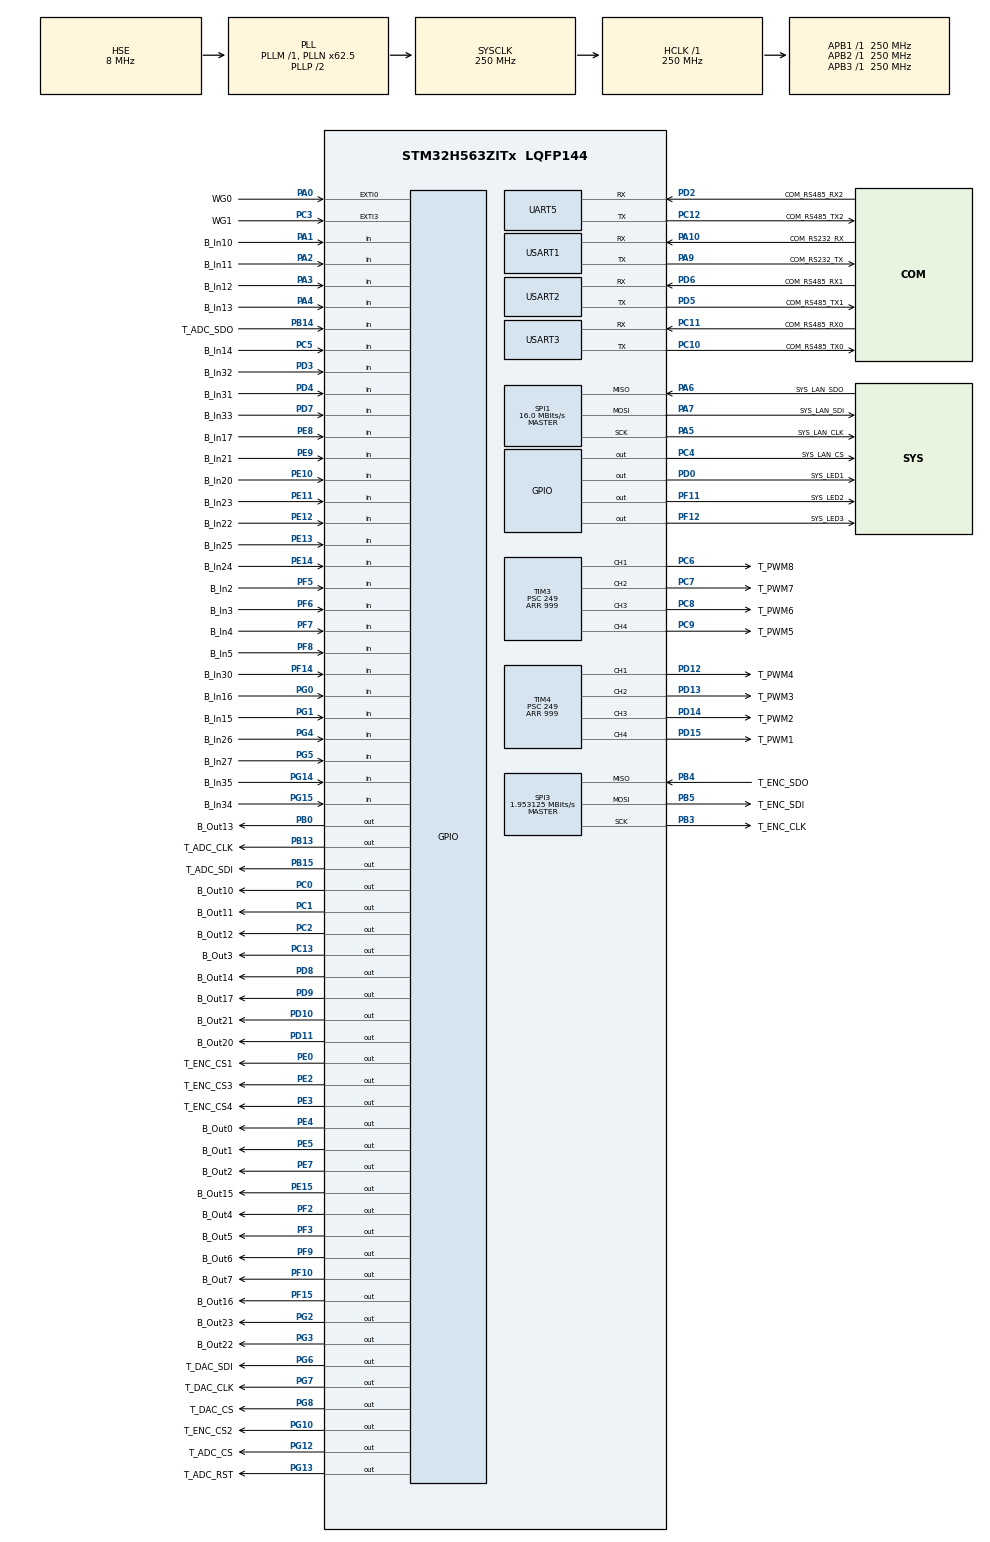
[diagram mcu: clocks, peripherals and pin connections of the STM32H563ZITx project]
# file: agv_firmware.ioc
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BOOTPATH.BootPathName=LEGACY
BOOTPATH.UserSelectedBootPath=LEGACY
CORTEX_M33_NS.userName=CORTEX_M33
GPDMA1.CIRCULARMODE_GPDMACH0=ENABLE
GPDMA1.CIRCULARMODE_GPDMACH1=ENABLE
GPDMA1.CIRCULARMODE_GPDMACH2=ENABLE
GPDMA1.CIRCULARMODE_GPDMACH3=ENABLE
GPDMA1.DESTINC_GPDMACH0=DMA_DINC_INCREMENTED
GPDMA1.DESTINC_GPDMACH1=DMA_DINC_INCREMENTED
GPDMA1.DESTINC_GPDMACH2=DMA_DINC_INCREMENTED
GPDMA1.DESTINC_GPDMACH3=DMA_DINC_INCREMENTED
GPDMA1.IPHANDLE_GPDMACH0-SIMPLEREQUEST_GPDMACH0=__NULL
GPDMA1.IPHANDLE_GPDMACH1-SIMPLEREQUEST_GPDMACH1=__NULL
GPDMA1.IPHANDLE_GPDMACH2-SIMPLEREQUEST_GPDMACH2=__NULL
GPDMA1.IPHANDLE_GPDMACH3-SIMPLEREQUEST_GPDMACH3=__NULL
GPDMA1.LINKALLOCATEDPORT_CIRCULAR_GPDMACH1=DMA_LINK_ALLOCATED_PORT1
GPDMA1.REQUEST_GPDMACH0=GPDMA1_REQUEST_USART3_RX
GPDMA1.REQUEST_GPDMACH1=GPDMA1_REQUEST_USART2_RX
GPDMA1.REQUEST_GPDMACH2=GPDMA1_REQUEST_UART5_RX
GPDMA1.REQUEST_GPDMACH3=GPDMA1_REQUEST_USART1_RX
GPDMA1.SRCINC_GPDMACH0=DMA_SINC_INCREMENTED
GPDMA1.SRCINC_GPDMACH3=DMA_SINC_FIXED
Mcu.Family=STM32H5
Mcu.Name=STM32H563ZITx
Mcu.Package=LQFP144
NVIC.EXTI0_IRQn=true\:0\:0\:false\:false\:true\:true\:true\:true
NVIC.EXTI3_IRQn=true\:0\:0\:false\:false\:true\:true\:true\:true
NVIC.GPDMA1_Channel0_IRQn=true\:0\:0\:false\:false\:true\:false\:true\:true
NVIC.GPDMA1_Channel1_IRQn=true\:0\:0\:false\:false\:true\:false\:true\:true
NVIC.GPDMA1_Channel2_IRQn=true\:0\:0\:false\:false\:true\:false\:true\:true
NVIC.GPDMA1_Channel3_IRQn=true\:0\:0\:false\:false\:true\:false\:true\:true
NVIC.PriorityGroup=NVIC_PRIORITYGROUP_4
NVIC.TIM3_IRQn=true\:0\:0\:false\:false\:true\:true\:true\:true
NVIC.TIM6_IRQn=true\:0\:0\:false\:false\:true\:true\:true\:true
NVIC.TIM7_IRQn=true\:3\:0\:true\:false\:true\:true\:true\:true
NVIC.UART5_IRQn=true\:0\:0\:false\:false\:true\:true\:true\:true
NVIC.USART1_IRQn=true\:0\:0\:false\:false\:true\:true\:true\:true
NVIC.USART2_IRQn=true\:0\:0\:false\:false\:true\:true\:true\:true
NVIC.USART3_IRQn=true\:0\:0\:false\:false\:true\:true\:true\:true
PA0.GPIO_Label=WG0
PA0.GPIO_ModeDefaultEXTI=GPIO_MODE_IT_FALLING
PA0.GPIO_PuPd=GPIO_PULLUP
PA0.Signal=GPXTI0
PA1.GPIO_Label=B_In10
PA1.Signal=GPIO_Input
PA10.GPIO_Label=COM_RS232_RX
PA10.Mode=Asynchronous
PA10.Signal=USART1_RX
PA13(JTMS/SWDIO).Mode=Serial_Wire
PA13(JTMS/SWDIO).Signal=DEBUG_JTMS-SWDIO
PA14(JTCK/SWCLK).Mode=Serial_Wire
PA14(JTCK/SWCLK).Signal=DEBUG_JTCK-SWCLK
PA2.GPIO_Label=B_In11
PA2.Signal=GPIO_Input
PA3.GPIO_Label=B_In12
PA3.Signal=GPIO_Input
PA4.GPIO_Label=B_In13
PA4.Signal=GPIO_Input
PA5.GPIO_Label=SYS_LAN_CLK
PA5.Mode=Full_Duplex_Master
PA5.Signal=SPI1_SCK
PA6.GPIO_Label=SYS_LAN_SDO
PA6.Mode=Full_Duplex_Master
PA6.Signal=SPI1_MISO
PA7.GPIO_Label=SYS_LAN_SDI
PA7.Mode=Full_Duplex_Master
PA7.Signal=SPI1_MOSI
PA9.GPIO_Label=COM_RS232_TX
PA9.Mode=Asynchronous
PA9.Signal=USART1_TX
PB0.GPIO_Label=B_Out13
PB0.Signal=GPIO_Output
PB13.GPIO_Label=T_ADC_CLK
PB13.Signal=GPIO_Output
PB14.GPIO_Label=T_ADC_SDO
PB14.GPIO_PuPd=GPIO_PULLUP
PB14.Signal=GPIO_Input
PB15.GPIO_Label=T_ADC_SDI
PB15.Signal=GPIO_Output
PB3(JTDO/TRACESWO).GPIO_Label=T_ENC_CLK
PB3(JTDO/TRACESWO).GPIO_Speed=GPIO_SPEED_FREQ_VERY_HIGH
PB3(JTDO/TRACESWO).Mode=Full_Duplex_Master
PB3(JTDO/TRACESWO).Signal=SPI3_SCK
PB4(NJTRST).GPIO_Label=T_ENC_SDO
PB4(NJTRST).GPIO_Speed=GPIO_SPEED_FREQ_VERY_HIGH
PB4(NJTRST).Mode=Full_Duplex_Master
PB4(NJTRST).Signal=SPI3_MISO
PB5.GPIO_Label=T_ENC_SDI
PB5.GPIO_Speed=GPIO_SPEED_FREQ_VERY_HIGH
PB5.Mode=Full_Duplex_Master
PB5.Signal=SPI3_MOSI
PC0.GPIO_Label=B_Out10
PC0.Signal=GPIO_Output
PC1.GPIO_Label=B_Out11
PC1.Signal=GPIO_Output
PC10.GPIO_Label=COM_RS485_TX0
PC10.Mode=Asynchronous
PC10.Signal=USART3_TX
PC11.GPIO_Label=COM_RS485_RX0
PC11.Mode=Asynchronous
PC11.Signal=USART3_RX
PC12.GPIO_Label=COM_RS485_TX2
PC12.Mode=Asynchronous
PC12.Signal=UART5_TX
PC13.GPIO_Label=B_Out3
PC13.Signal=GPIO_Output
PC2.GPIO_Label=B_Out12
PC2.Signal=GPIO_Output
PC3.GPIO_Label=WG1
PC3.GPIO_ModeDefaultEXTI=GPIO_MODE_IT_FALLING
PC3.GPIO_PuPd=GPIO_PULLUP
PC3.Signal=GPXTI3
PC4.GPIO_Label=SYS_LAN_CS
PC4.Signal=GPIO_Output
PC5.GPIO_Label=B_In14
PC5.Signal=GPIO_Input
PC6.GPIO_Label=T_PWM8
PC6.Signal=S_TIM3_CH1
PC7.GPIO_Label=T_PWM7
PC7.Signal=S_TIM3_CH2
PC8.GPIO_Label=T_PWM6
PC8.Signal=S_TIM3_CH3
PC9.GPIO_Label=T_PWM5
PC9.Signal=S_TIM3_CH4
PD0.GPIO_Label=SYS_LED1
PD0.Signal=GPIO_Output
PD10.GPIO_Label=B_Out21
PD10.Signal=GPIO_Output
PD11.GPIO_Label=B_Out20
PD11.Signal=GPIO_Output
PD12.GPIO_Label=T_PWM4
PD12.Signal=S_TIM4_CH1
PD13.GPIO_Label=T_PWM3
PD13.PinAttribute=Free
PD13.Signal=S_TIM4_CH2
PD14.GPIO_Label=T_PWM2
PD14.Signal=S_TIM4_CH3
PD15.GPIO_Label=T_PWM1
PD15.Signal=S_TIM4_CH4
PD2.GPIO_Label=COM_RS485_RX2
PD2.Mode=Asynchronous
PD2.Signal=UART5_RX
PD3.GPIO_Label=B_In32
PD3.GPIO_PuPd=GPIO_PULLUP
PD3.Signal=GPIO_Input
PD4.GPIO_Label=B_In31
PD4.GPIO_PuPd=GPIO_PULLUP
PD4.Signal=GPIO_Input
PD5.GPIO_Label=COM_RS485_TX1
PD5.Mode=Asynchronous
PD5.Signal=USART2_TX
PD6.GPIO_Label=COM_RS485_RX1
PD6.Mode=Asynchronous
PD6.Signal=USART2_RX
PD7.GPIO_Label=B_In33
PD7.GPIO_PuPd=GPIO_PULLUP
PD7.Signal=GPIO_Input
PD8.GPIO_Label=B_Out14
PD8.Signal=GPIO_Output
PD9.GPIO_Label=B_Out17
PD9.Signal=GPIO_Output
PE0.GPIO_Label=T_ENC_CS1
PE0.GPIO_Speed=GPIO_SPEED_FREQ_VERY_HIGH
PE0.Signal=GPIO_Output
PE10.GPIO_Label=B_In20
PE10.GPIO_PuPd=GPIO_PULLUP
PE10.Signal=GPIO_Input
PE11.GPIO_Label=B_In23
PE11.GPIO_PuPd=GPIO_PULLUP
PE11.Signal=GPIO_Input
PE12.GPIO_Label=B_In22
PE12.GPIO_PuPd=GPIO_PULLUP
PE12.Signal=GPIO_Input
PE13.GPIO_Label=B_In25
PE13.GPIO_PuPd=GPIO_PULLUP
PE13.Signal=GPIO_Input
PE14.GPIO_Label=B_In24
PE14.GPIO_PuPd=GPIO_PULLUP
PE14.Signal=GPIO_Input
PE15.GPIO_Label=B_Out15
PE15.Signal=GPIO_Output
PE2.GPIO_Label=T_ENC_CS3
PE2.GPIO_Speed=GPIO_SPEED_FREQ_VERY_HIGH
PE2.Signal=GPIO_Output
PE3.GPIO_Label=T_ENC_CS4
PE3.GPIO_Speed=GPIO_SPEED_FREQ_VERY_HIGH
PE3.Signal=GPIO_Output
PE4.GPIO_Label=B_Out0
PE4.Signal=GPIO_Output
PE5.GPIO_Label=B_Out1
PE5.Signal=GPIO_Output
PE7.GPIO_Label=B_Out2
PE7.Signal=GPIO_Output
PE8.GPIO_Label=B_In17
PE8.GPIO_PuPd=GPIO_PULLUP
PE8.Signal=GPIO_Input
PE9.GPIO_Label=B_In21
PE9.GPIO_PuPd=GPIO_PULLUP
PE9.Signal=GPIO_Input
PF10.GPIO_Label=B_Out7
PF10.Signal=GPIO_Output
PF11.GPIO_Label=SYS_LED2
PF11.Signal=GPIO_Output
PF12.GPIO_Label=SYS_LED3
PF12.Signal=GPIO_Output
PF14.GPIO_Label=B_In30
PF14.GPIO_PuPd=GPIO_PULLUP
PF14.Signal=GPIO_Input
PF15.GPIO_Label=B_Out16
PF15.Signal=GPIO_Output
PF2.GPIO_Label=B_Out4
PF2.Signal=GPIO_Output
PF3.GPIO_Label=B_Out5
PF3.Signal=GPIO_Output
PF5.GPIO_Label=B_In2
PF5.Signal=GPIO_Input
PF6.GPIO_Label=B_In3
PF6.Signal=GPIO_Input
PF7.GPIO_Label=B_In4
PF7.Signal=GPIO_Input
PF8.GPIO_Label=B_In5
PF8.Signal=GPIO_Input
PF9.GPIO_Label=B_Out6
PF9.Signal=GPIO_Output
PG0.GPIO_Label=B_In16
PG0.GPIO_PuPd=GPIO_PULLUP
PG0.Signal=GPIO_Input
PG1.GPIO_Label=B_In15
PG1.Signal=GPIO_Input
PG10.GPIO_Label=T_ENC_CS2
PG10.GPIO_Speed=GPIO_SPEED_FREQ_VERY_HIGH
PG10.Signal=GPIO_Output
PG12.GPIO_Label=T_ADC_CS
PG12.Signal=GPIO_Output
PG13.GPIO_Label=T_ADC_RST
PG13.Signal=GPIO_Output
PG14.GPIO_Label=B_In35
PG14.GPIO_Mode=GPIO_MODE_INPUT
PG14.GPIO_PuPd=GPIO_PULLUP
PG14.Signal=GPIO_Input
PG15.GPIO_Label=B_In34
PG15.GPIO_Mode=GPIO_MODE_INPUT
PG15.GPIO_PuPd=GPIO_PULLUP
PG15.Signal=GPIO_Input
PG2.GPIO_Label=B_Out23
PG2.Signal=GPIO_Output
PG3.GPIO_Label=B_Out22
PG3.Signal=GPIO_Output
PG4.GPIO_Label=B_In26
PG4.GPIO_PuPd=GPIO_PULLUP
PG4.Signal=GPIO_Input
PG5.GPIO_Label=B_In27
PG5.GPIO_PuPd=GPIO_PULLUP
PG5.Signal=GPIO_Input
PG6.GPIO_Label=T_DAC_SDI
PG6.Signal=GPIO_Output
PG7.GPIO_Label=T_DAC_CLK
PG7.Signal=GPIO_Output
PG8.GPIO_Label=T_DAC_CS
PG8.Signal=GPIO_Output
PH0-OSC_IN(PH0).Mode=HSE-External-Oscillator
PH0-OSC_IN(PH0).Signal=RCC_OSC_IN
PH1-OSC_OUT(PH1).Mode=HSE-External-Oscillator
PH1-OSC_OUT(PH1).Signal=RCC_OSC_OUT
ProjectManager.HeapSize=0x200
ProjectManager.StackSize=0x400
ProjectManager.TargetToolchain=STM32CubeIDE
RCC.ADCFreq_Value=250000000
RCC.AHBFreq_Value=250000000
RCC.APB1Freq_Value=250000000
RCC.APB1TimFreq_Value=250000000
RCC.APB2Freq_Value=250000000
RCC.APB2TimFreq_Value=250000000
RCC.APB3Freq_Value=250000000
RCC.CSI_VALUE=4000000
RCC.CortexFreq_Value=250000000
RCC.EPOD_VALUE=8000000
RCC.EnbaleCSS=true
RCC.HCLKFreq_Value=250000000
RCC.HSE_VALUE=8000000
RCC.HSI48_VALUE=48000000
RCC.HSI_VALUE=64000000
RCC.LSE_VALUE=32768
RCC.LSIRC_VALUE=32000
RCC.PLL1Q=4
RCC.PLL2FRACN=0
RCC.PLL3FRACN=0
RCC.PLLFRACN=4096
RCC.PLLN=62
RCC.PLLSourceVirtual=RCC_PLL1_SOURCE_HSE
RCC.SPI1CLockSelection=RCC_SPI1CLKSOURCE_CLKP
RCC.SYSCLKFreq_VALUE=250000000
RCC.SYSCLKSource=RCC_SYSCLKSOURCE_PLLCLK
RCC.USBFreq_Value=48000000
RCC.VCOOutputFreq_Value=500000000
SH.S_TIM3_CH1.0=TIM3_CH1,PWM Generation1 CH1
SH.S_TIM3_CH2.0=TIM3_CH2,PWM Generation2 CH2
SH.S_TIM3_CH3.0=TIM3_CH3,PWM Generation3 CH3
SH.S_TIM3_CH4.0=TIM3_CH4,PWM Generation4 CH4
SH.S_TIM4_CH1.0=TIM4_CH1,PWM Generation1 CH1
SH.S_TIM4_CH2.0=TIM4_CH2,PWM Generation2 CH2
SH.S_TIM4_CH3.0=TIM4_CH3,PWM Generation3 CH3
SH.S_TIM4_CH4.0=TIM4_CH4,PWM Generation4 CH4
SPI1.CalculateBaudRate=16.0 MBits/s
SPI1.Direction=SPI_DIRECTION_2LINES
SPI1.Mode=SPI_MODE_MASTER
SPI1.VirtualType=VM_MASTER
SPI3.BaudRatePrescaler=SPI_BAUDRATEPRESCALER_64
SPI3.CalculateBaudRate=1.953125 MBits/s
SPI3.DataSize=SPI_DATASIZE_8BIT
SPI3.Direction=SPI_DIRECTION_2LINES
SPI3.Mode=SPI_MODE_MASTER
SPI3.VirtualType=VM_MASTER
TIM3.AutoReloadPreload=TIM_AUTORELOAD_PRELOAD_ENABLE
TIM3.Channel-PWM\ Generation1\ CH1=TIM_CHANNEL_1
TIM3.Channel-PWM\ Generation2\ CH2=TIM_CHANNEL_2
TIM3.Channel-PWM\ Generation3\ CH3=TIM_CHANNEL_3
TIM3.Channel-PWM\ Generation4\ CH4=TIM_CHANNEL_4
TIM3.PeriodNoDither=999
TIM3.Prescaler=249
TIM4.Channel-PWM\ Generation1\ CH1=TIM_CHANNEL_1
TIM4.Channel-PWM\ Generation2\ CH2=TIM_CHANNEL_2
TIM4.Channel-PWM\ Generation3\ CH3=TIM_CHANNEL_3
TIM4.Channel-PWM\ Generation4\ CH4=TIM_CHANNEL_4
TIM4.PeriodNoDither=999
TIM4.Prescaler=249
TIM6.PeriodNoDither=9999
TIM6.Prescaler=249
TIM7.PeriodNoDither=9999
TIM7.Prescaler=249
USART1.VirtualMode-Asynchronous=VM_ASYNC
USART2.VirtualMode-Asynchronous=VM_ASYNC
USART3.VirtualMode-Asynchronous=VM_ASYNC
VP_BOOTPATH_VS_BOOTPATH.Mode=BP_Activate
VP_CORTEX_M33_NS_VS_Hclk.Mode=Hclk_Mode
VP_GPDMA1_VS_GPDMACH0.Mode=SIMPLEREQUEST_GPDMACH0
VP_GPDMA1_VS_GPDMACH1.Mode=SIMPLEREQUEST_GPDMACH1
VP_GPDMA1_VS_GPDMACH2.Mode=SIMPLEREQUEST_GPDMACH2
VP_GPDMA1_VS_GPDMACH3.Mode=SIMPLEREQUEST_GPDMACH3
VP_ICACHE_VS_ENABLE_ICACHE_MEMORY.Mode=Memoryregions
VP_MEMORYMAP_VS_MEMORYMAP.Mode=CurAppReg
VP_PWR_VS_LPOM.Mode=PowerOptimisation
VP_PWR_VS_SECSignals.Mode=Security/Privilege
VP_TIM3_VS_ClockSourceINT.Mode=Internal
VP_TIM6_VS_ClockSourceINT.Mode=Enable_Timer
VP_TIM7_VS_ClockSourceINT.Mode=Enable_Timer
board=custom

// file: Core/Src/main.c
/* USER CODE BEGIN Header */
/**
 ******************************************************************************
 * @file           : main.c
 * @brief          : Main program body
 ******************************************************************************
 * @attention
 *
 * Copyright (c) 2026 STMicroelectronics.
 * All rights reserved.
 *
 * This software is licensed under terms that can be found in the LICENSE file
 * in the root directory of this software component.
 * If no LICENSE file comes with this software, it is provided AS-IS.
 *
 ******************************************************************************
 */
/* USER CODE END Header */
#include "main.h"
#include "gpdma.h"
#include "gpio.h"
#include "icache.h"
#include "spi.h"
#include "tim.h"
#include "usart.h"

/* USER CODE BEGIN Includes */
#include "agv_control.h"
#include "agv_eeprom.h"
#include "agv_routing.h"
#include "esp32_hub.h" // Thư viện giao tiếp ESP32
#include "hmi_modbus.h"
#include "qr50_reader.h"

// #include "wiegand.h"
#include "agv_eeprom.h"
#include "ls7366r.h"
#include "motor.h"
#include "sensor.h"
#include "ads8688.h"
#include <agv_body_step.h>
#include <stdlib.h> // Để sử dụng hàm atoi
#include <string.h>

/* USER CODE END Includes */

/* USER CODE BEGIN PTD */
volatile uint32_t spi_test_result_e1 = 0;
volatile uint32_t spi_test_result_e2 = 0;
/* USER CODE END PTD */

/* USER CODE BEGIN PV */
volatile uint32_t dbg_huart3_rx_byte_count   = 0;
volatile uint32_t dbg_huart3_rx_ok           = 0;
volatile uint32_t dbg_huart3_rx_err          = 0;
volatile uint8_t  huart3_rx_byte             = 0;
volatile float    dbg_huart3_joints_left[6]  = {0.0f};
volatile float    dbg_huart3_joints_right[6] = {0.0f};
volatile char     dbg_huart3_last_type       = 0;

static char       huart3_rx_line[128];
static uint8_t    huart3_rx_line_idx         = 0;

// Các biến phục vụ việc xem trực tiếp trên Live Expression
volatile uint32_t debug_rfid_rx_count = 0;
volatile uint16_t debug_rfid_rx_len = 0;
volatile uint8_t debug_rfid_rx_buf[64] = {0};
volatile uint32_t debug_rfid_err_count = 0;
volatile uint8_t debug_rx_byte = 0;      // Byte nhận tạm thời cho ngắt IT
volatile uint32_t debug_qr_rx_count = 0; // Đếm số lần nhảy vào ngắt nhận QR50
volatile uint32_t debug_qr_err_count = 0; // Đếm số lần bị lỗi khung truyền (Baudrate)
volatile uint32_t debug_hmi_rx_count = 0; // Đếm số lần nhận được ngắt từ HMI
float adc_feedback_ch0 = 0.0f;
volatile uint32_t dbg_tim7_count = 0;       // Đếm số lần TIM7 ISR chạy
volatile uint16_t dbg_ads_raw0 = 0;         // Giá trị ADC thô CH0
volatile uint16_t dbg_ads_raw1 = 0;         // Giá trị ADC thô CH1
volatile uint8_t  dbg_ads_spi_test = 0xFF;  // Kết quả test SPI (0x06=OK, 0=SPI fail)
volatile uint8_t  dbg_ads_pin_rst = 0;      // PG13 RST: kỳ vọng 1 (HIGH) sau init
volatile uint8_t  dbg_ads_pin_cs  = 0;      // PG12 CS:  kỳ vọng 1 (HIGH, idle)
volatile uint8_t  dbg_ads_pin_sdo = 1;      // PB14 SDO: trạng thái idle của MISO
volatile uint8_t  dbg_ads_scan_results[16] = {0}; // Mảng kết quả tự động scan 16 combo (Kỳ vọng combo đúng trả về 0x06)
// === BIẾN GLOBAL ĐỂ DEBUG TRÊN LIVE EXPRESSION ===
AGV_HandleTypeDef h_agv;
Motor_HandleTypeDef m_left, m_right;
LineSensor_HandleTypeDef line_ss;
Pid_data pid_ctrl;
QR50_Handler_t qr50;
uint8_t qr50_rx_buffer[QR50_MAX_DATA_LEN];
Wiegand_HandleTypeDef h_wiegand;
volatile uint32_t debug_wiegand_id = 0; // ID thẻ Wiegand (Live Expression)
volatile uint32_t debug_wiegand_bit_count = 0; // Số bit nhận được (phải = 34)
volatile uint64_t debug_wiegand_raw =
    0; // Raw 34 bit trước khi decode (để chẩn đoán)
volatile uint32_t debug_wiegand_high32 = 0;
volatile uint32_t debug_wiegand_low32 = 0;
// Step thân robot
volatile step_command_t cmd = {.angle = 0, .rpm = 30};
static step_command_t cmd_prev = {0};

// --- CẤU HÌNH MÃ THẺ RFID CỦA TỪNG TRẠM ---
#define RFID_NODE_0 N00
#define RFID_NODE_1 N01
#define RFID_NODE_2 N02
#define RFID_NODE_3 N03
#define RFID_NODE_4 N04
#define RFID_NODE_5 N05
#define RFID_NODE_6 N06
#define RFID_NODE_7 N07
#define RFID_NODE_8 N08

// Mảng ánh xạ RFID sang Node ID (Chỉ mục là Node ID, giá trị là Wiegand ID)
uint32_t rfid_node_map[MAX_NODES] = {
    [0] = RFID_NODE_0, [1] = RFID_NODE_1, [2] = RFID_NODE_2,
    [3] = RFID_NODE_3, [4] = RFID_NODE_4, [5] = RFID_NODE_5,
    [6] = RFID_NODE_6, [7] = RFID_NODE_7, [8] = RFID_NODE_8,
};
volatile LS7366R_EncoderData_t encoder_data;
ADS8688_HandleTypeDef h_ads8688;
AGV_Map_t factory_map;
AGV_Heading_t current_heading = HEAD_NORTH;
extern AGV_State_t agv_state;
extern AGV_Config_t agv_config;
extern ESP32_SensorData_t esp32_data;
extern HMI_HandleTypeDef h_hmi;

uint16_t current_path[MAX_NODES];
uint16_t path_length = 0;
static uint16_t last_processed_node = 0xFFFF;
char debug_line_binary[17] = "0000000000000000";
uint16_t pending_qr_node = 0xFFFF;
uint32_t blind_zone_end_time = 0;
uint32_t calib_time_offset = 750;
uint32_t calib_time_turn_90 = 3500;
volatile uint32_t mode6_stop_time = 0;

GPIO_TypeDef *sensor_ports[16] = {
    B_In35_GPIO_Port, B_In34_GPIO_Port, B_In33_GPIO_Port, B_In32_GPIO_Port,
    B_In31_GPIO_Port, B_In30_GPIO_Port, B_In27_GPIO_Port, B_In26_GPIO_Port,
    B_In25_GPIO_Port, B_In24_GPIO_Port, B_In23_GPIO_Port, B_In22_GPIO_Port,
    B_In21_GPIO_Port, B_In20_GPIO_Port, B_In17_GPIO_Port, B_In16_GPIO_Port};
uint16_t sensor_pins[16] = {B_In35_Pin, B_In34_Pin, B_In33_Pin, B_In32_Pin,
                            B_In31_Pin, B_In30_Pin, B_In27_Pin, B_In26_Pin,
                            B_In25_Pin, B_In24_Pin, B_In23_Pin, B_In22_Pin,
                            B_In21_Pin, B_In20_Pin, B_In17_Pin, B_In16_Pin};

/* USER CODE END PV */

void SystemClock_Config(void);
void PeriphCommonClock_Config(void);

/* USER CODE BEGIN 0 */
#define AGV_ARM_FORWARD_PERIOD_MS 20u

#if 0
static bool AGV_IsLegacyArmCommand(const char *arm_command) {
  return arm_command != NULL &&
         (arm_command[0] == 'L' || arm_command[0] == 'R') &&
         arm_command[1] == ':';
}

static void AGV_ForwardArmCommand(const char *arm_command) {
  if (arm_command == NULL) {
    return;
  }

  size_t cmd_len = strnlen(arm_command, ESP32_MAX_ARM_CMD_LEN);
  if (cmd_len < 3) {
    return;
  }

  if (!AGV_IsLegacyArmCommand(arm_command)) {
    return;
  }

  uint8_t tx_buffer[ESP32_MAX_ARM_CMD_LEN + 2];
  memcpy(tx_buffer, arm_command, cmd_len);

  if (tx_buffer[cmd_len - 1] != '\n') {
    tx_buffer[cmd_len++] = '\n';
  }

  // Temporarily skipped to prevent unconnected UART3 hang
  // HAL_UART_Transmit(&huart3, tx_buffer, (uint16_t)cmd_len, 50);
}
#endif

static void AGV_HandleEsp32Safety(AGV_HandleTypeDef *hagv,
                                  const ESP32_SensorData_t *safe_esp32_data) {
  if (safe_esp32_data == NULL || hagv == NULL)
    return;

  if (!safe_esp32_data->IsConnected)
    return;

  if (safe_esp32_data->Yaw == 65535.0f ||
      safe_esp32_data->ObstacleDistance == 0xFFFF) {
    if (agv_state.follow_line_enable) {
      agv_state.follow_line_enable = false;
      AGV_Stop(hagv);
    }
    return;
  }

  // --- LOGIC VẬT CẢN (VL53L5CX) ---
  bool is_obstacle = false;
  if (safe_esp32_data->ObstacleDistance < 500) {
    bool is_exception = false;
    // Ngoại trừ các đoạn sát tường: 1->0, 4->3, 7->6
    if (path_length > 0 && agv_state.path_index < path_length - 1) {
      uint16_t current_n = current_path[agv_state.path_index];
      uint16_t next_n = current_path[agv_state.path_index + 1];
      if ((current_n == 1 && next_n == 0) || (current_n == 4 && next_n == 3) ||
          (current_n == 7 && next_n == 6)) {
        is_exception = true;
      }
    }

    if (!is_exception) {
      is_obstacle = true;
    }
  }

  static bool paused_by_obstacle = false;

  if (is_obstacle) {
    if (agv_state.follow_line_enable && agv_state.run_mode == MODE_4_FULL_RUN) {
      agv_state.follow_line_enable = false;
      AGV_Stop(hagv);
      paused_by_obstacle = true;
    }
  } else {
    if (paused_by_obstacle) {
      if (agv_state.run_mode == MODE_4_FULL_RUN) {
        agv_state.follow_line_enable = true; // Đi tiếp khi vật cản rời đi
        // Quan trọng: Reset lại bộ đếm timeout QR 15s để tránh bị báo lỗi mất
        // line ngay lập tức
        agv_state.last_qr_time = HAL_GetTick();
      }
      paused_by_obstacle = false;
    }
  }
}

static void AGV_ServiceEsp32Request(uint32_t *last_esp32_req_time) {
  if (last_esp32_req_time == NULL)
    return;

  if (HAL_GetTick() - *last_esp32_req_time > 20) {
    *last_esp32_req_time = HAL_GetTick();
    uint8_t is_arrived =
        (agv_state.current_node == agv_state.destination_node) ? 1 : 0;
    ESP32_RequestData(agv_state.current_node, is_arrived);
  }
}

static void AGV_ServiceHeartbeat(uint32_t *last_led_time) {
  if (last_led_time == NULL)
    return;

  if (HAL_GetTick() - *last_led_time <= 500)
    return;

  *last_led_time = HAL_GetTick();
  HAL_GPIO_TogglePin(SYS_LED1_GPIO_Port, SYS_LED1_Pin);
  __HAL_UART_CLEAR_FLAG(&huart5, UART_CLEAR_OREF | UART_CLEAR_NEF |
                                     UART_CLEAR_FEF | UART_CLEAR_PEF);

  if (HAL_GetTick() - esp32_data.LastUpdateTick > 2000) {
    extern uint8_t esp32_rx_buffer[128];
    HAL_UART_AbortReceive(&huart5);
    HAL_UARTEx_ReceiveToIdle_DMA(&huart5, esp32_rx_buffer,
                                 sizeof(esp32_rx_buffer));
  }
}

static uint8_t mode5_calib_state = 0;
static uint32_t mode5_calib_start_time = 0;

static bool AGV_HandleMode5Calibration(void) {

  if (!ESP32_GetSafeData().IsConnected) {
    AGV_Stop(&h_agv);
    return true;
  }

  agv_state.follow_line_enable = false;

  if (mode5_calib_start_time == 0)
    mode5_calib_start_time = HAL_GetTick();

  uint32_t elapsed = HAL_GetTick() - mode5_calib_start_time;

  switch (mode5_calib_state) {
  case 0:
    AGV_Stop(&h_agv);
    if (elapsed > 2000) {
      mode5_calib_state++;
      mode5_calib_start_time = HAL_GetTick();
    }
    break;
  case 1:
    Motor_SetSpeed(&m_left, agv_config.turn_speed);
    Motor_SetSpeed(&m_right, agv_config.turn_speed);
    if (elapsed > agv_config.time_forward) {
      mode5_calib_state++;
      mode5_calib_start_time = HAL_GetTick();
    }
    break;
  case 2:
    AGV_Stop(&h_agv);
    if (elapsed > 1000) {
      mode5_calib_state++;
      mode5_calib_start_time = HAL_GetTick();
    }
    break;
  case 3:
    Motor_SetSpeed(&m_left, -agv_config.turn_speed);
    Motor_SetSpeed(&m_right, -agv_config.turn_speed);
    if (elapsed > agv_config.time_forward) {
      mode5_calib_state++;
      mode5_calib_start_time = HAL_GetTick();
    }
    break;
  case 4:
    AGV_Stop(&h_agv);
    if (elapsed > 1000) {
      mode5_calib_state++;
      mode5_calib_start_time = HAL_GetTick();
    }
    break;
  case 5:
    AGV_TurnLeft_IMU(&h_agv, 800, 0.70f);
    mode5_calib_state++;
    mode5_calib_start_time = HAL_GetTick();
    break;
  case 6:
    AGV_Stop(&h_agv);
    if (elapsed > 1000) {
      mode5_calib_state++;
      mode5_calib_start_time = HAL_GetTick();
    }
    break;
  case 7:
    AGV_Turn180_IMU(&h_agv, 0); // 0 = HEAD_NORTH
    mode5_calib_state++;
    mode5_calib_start_time = HAL_GetTick();
    break;
  case 8:
    AGV_Stop(&h_agv);
    if (elapsed > 1000) {
      mode5_calib_state++;
      mode5_calib_start_time = HAL_GetTick();
    }
    break;
  case 9:
    Motor_SetSpeed(&m_left, -agv_config.turn_speed);
    Motor_SetSpeed(&m_right, agv_config.turn_speed);
    if (elapsed > agv_config.time_turn_180) {
      mode5_calib_state++;
      mode5_calib_start_time = HAL_GetTick();
    }
    break;
  case 10:
    AGV_Stop(&h_agv);
    if (elapsed > 1000) {
      mode5_calib_state++;
      mode5_calib_start_time = HAL_GetTick();
    }
    break;
  case 11:
    Motor_SetSpeed(&m_left, agv_config.turn_speed);
    Motor_SetSpeed(&m_right, -agv_config.turn_speed);
    if (elapsed > agv_config.time_turn_180) {
      mode5_calib_state++;
      mode5_calib_start_time = HAL_GetTick();
    }
    break;
  default:
    AGV_Stop(&h_agv);
    return false;
  }

  return true;
}

/**
 * @brief Toggle all Output pins for hardware verification
 * @note Excludes Input pins (B_InX, SDO, RX) to avoid electrical conflict
 */
void Toggle_Outputs(void) {
  HAL_GPIO_TogglePin(B_Out0_GPIO_Port, B_Out0_Pin);
  HAL_GPIO_TogglePin(B_Out1_GPIO_Port, B_Out1_Pin);
  HAL_GPIO_TogglePin(B_Out2_GPIO_Port, B_Out2_Pin);
  HAL_GPIO_TogglePin(B_Out3_GPIO_Port, B_Out3_Pin);
  HAL_GPIO_TogglePin(B_Out4_GPIO_Port, B_Out4_Pin);
  HAL_GPIO_TogglePin(B_Out5_GPIO_Port, B_Out5_Pin);
  HAL_GPIO_TogglePin(B_Out6_GPIO_Port, B_Out6_Pin);
  HAL_GPIO_TogglePin(B_Out7_GPIO_Port, B_Out7_Pin);
  HAL_GPIO_TogglePin(B_Out10_GPIO_Port, B_Out10_Pin);
  HAL_GPIO_TogglePin(B_Out11_GPIO_Port, B_Out11_Pin);
  HAL_GPIO_TogglePin(B_Out12_GPIO_Port, B_Out12_Pin);
  HAL_GPIO_TogglePin(B_Out13_GPIO_Port, B_Out13_Pin);
  HAL_GPIO_TogglePin(B_Out14_GPIO_Port, B_Out14_Pin);
  HAL_GPIO_TogglePin(B_Out15_GPIO_Port, B_Out15_Pin);
  HAL_GPIO_TogglePin(B_Out16_GPIO_Port, B_Out16_Pin);
  HAL_GPIO_TogglePin(B_Out17_GPIO_Port, B_Out17_Pin);
  HAL_GPIO_TogglePin(B_Out20_GPIO_Port, B_Out20_Pin);
  HAL_GPIO_TogglePin(B_Out21_GPIO_Port, B_Out21_Pin);
  HAL_GPIO_TogglePin(B_Out22_GPIO_Port, B_Out22_Pin);
  HAL_GPIO_TogglePin(B_Out23_GPIO_Port, B_Out23_Pin);

  HAL_GPIO_TogglePin(SYS_LED1_GPIO_Port, SYS_LED1_Pin);
  HAL_GPIO_TogglePin(SYS_LED2_GPIO_Port, SYS_LED2_Pin);
  HAL_GPIO_TogglePin(SYS_LED3_GPIO_Port, SYS_LED3_Pin);
}

void Load_Factory_Map(void) {
  Map_Init(&factory_map);
  factory_map.total_nodes = 9;

  Map_AddEdge(&factory_map, N00, N01, 1, HEAD_NORTH);
  Map_AddEdge(&factory_map, N01, N00, 1, HEAD_SOUTH);
  Map_AddEdge(&factory_map, N01, N02, 1, HEAD_NORTH);
  Map_AddEdge(&factory_map, N02, N01, 1, HEAD_SOUTH);

  Map_AddEdge(&factory_map, N03, N04, 1, HEAD_NORTH);
  Map_AddEdge(&factory_map, N04, N03, 1, HEAD_SOUTH);
  Map_AddEdge(&factory_map, N04, N05, 1, HEAD_NORTH);
  Map_AddEdge(&factory_map, N05, N04, 1, HEAD_SOUTH);

  Map_AddEdge(&factory_map, N06, N07, 1, HEAD_NORTH);
  Map_AddEdge(&factory_map, N07, N06, 1, HEAD_SOUTH);
  Map_AddEdge(&factory_map, N07, N08, 1, HEAD_NORTH);
  Map_AddEdge(&factory_map, N08, N07, 1, HEAD_SOUTH);

  Map_AddEdge(&factory_map, N02, N05, 1, HEAD_EAST);
  Map_AddEdge(&factory_map, N05, N02, 1, HEAD_WEST);

  Map_AddEdge(&factory_map, N05, N08, 1, HEAD_EAST);
  Map_AddEdge(&factory_map, N08, N05, 1, HEAD_WEST);
}

static void AGV_HandleIntersectionRouting(uint16_t *pending_qr_node,
                                          uint16_t *last_processed_node,
                                          uint16_t *path_length,
                                          AGV_Heading_t *current_heading) {
  if (!agv_state.is_at_intersection)
    return;

  if (agv_state.run_mode == MODE_2_LINE_INTERSECTION)
    return;

  if (agv_state.run_mode == MODE_6_TEST_TURN_RIGHT) {
    AGV_TurnRight_IMU(&h_agv, 800, 0.70f);
    agv_state.last_leave_intersection_time = HAL_GetTick();
    agv_state.is_at_intersection = false;
    agv_state.follow_line_enable = true;
    return;
  }

  if (agv_state.run_mode == MODE_7_DEBUG_NO_QR) {
    if (*path_length > 0 && agv_state.path_index < *path_length - 1) {
      *pending_qr_node = current_path[agv_state.path_index + 1];
    } else {
      *pending_qr_node = agv_state.destination_node;
    }
  }

  static uint8_t nudge_count = 0;

  if (*pending_qr_node == 0xFFFF) {
    if (agv_state.run_mode == MODE_4_FULL_RUN) {
      if (HAL_GetTick() - agv_state.intersection_time > 1500) {
        if (nudge_count < 3) {
          AGV_BlindForward(&h_agv, 50); // Nhích tới 50ms
          AGV_Stop(&h_agv);
          nudge_count++;
          agv_state.intersection_time = HAL_GetTick();
        } else {
          // Báo lỗi nếu đã nhích 3 lần vẫn không thấy mã
          agv_state.indicator_state = 2;
        }
      }
    }
    return;
  }

  // Đã có mã QR, reset lại số lần nhích để dùng cho ngã tư sau
  nudge_count = 0;

  uint16_t read_node_id = *pending_qr_node;
  *pending_qr_node = 0xFFFF;
  *last_processed_node = read_node_id;
  agv_state.is_at_intersection = false;

  if (read_node_id == agv_state.destination_node) {
    agv_state.current_node = read_node_id;
    agv_state.path_index = 0;
    agv_state.follow_line_enable = false;
    AGV_Stop(&h_agv);
    // EEPROM_SaveState(agv_state.current_node, current_heading);
    return;
  }

  if (*path_length > 0 && agv_state.path_index < *path_length - 1 &&
      read_node_id == current_path[agv_state.path_index + 1]) {
    agv_state.path_index++;
    agv_state.current_node = read_node_id;
  } else if (read_node_id != agv_state.current_node) {
    agv_state.current_node = read_node_id;
    agv_state.is_kidnapped = true; // Bật cờ phát hiện bị bắt cóc
    bool found_path =
        Routing_Dijkstra(&factory_map, agv_state.current_node,
                         agv_state.destination_node, current_path, path_length);
    if (found_path) {
      agv_state.path_index = 0;
    } else {
      agv_state.follow_line_enable = false;
      AGV_Stop(&h_agv);
      return;
    }
  }

  if (*path_length > 0 && agv_state.path_index < *path_length - 1) {
    uint16_t next_node = current_path[agv_state.path_index + 1];
    AGV_Heading_t target_heading =
        Routing_GetHeading(&factory_map, agv_state.current_node, next_node);

    // Loại bỏ việc ép hướng khi bị "bắt cóc" (hoặc khi cố tình bỏ qua node).
    // AGV sẽ dùng chính hướng hiện tại (current_heading) để tính góc rẽ chính
    // xác.
    if (agv_state.is_kidnapped) {
      agv_state.is_kidnapped = false; // Xóa cờ, giữ nguyên current_heading
    }

    int diff = (target_heading - *current_heading + 4) % 4;

    uint32_t fwd_delay = 1900;
    float search_ratio = 0.70f;
    if (agv_state.current_node == 8 && next_node == 7) {
      fwd_delay = 1600;
    }

    if (agv_state.current_node == 2 && next_node == 5) {
      fwd_delay = 1800;
    }
    // Căn chỉnh riêng cho Node 5 để tránh bị văng quá đà khi rẽ
    if (agv_state.current_node == 5) {
      fwd_delay = 1700;
    }

    agv_state.follow_line_enable = false;
    switch ((AGV_Action_t)diff) {
    case ACT_TURN_LEFT:
      h_agv.direction = 1;
      AGV_TurnLeft_IMU(&h_agv, fwd_delay, search_ratio);
      break;
    case ACT_TURN_RIGHT:
      h_agv.direction = 1;
      AGV_TurnRight_IMU(&h_agv, fwd_delay, search_ratio);
      break;
    case ACT_STRAIGHT:
      h_agv.direction = 1;
      // Xe đã bị dừng tại ngã tư, cần chạy thẳng qua trước khi bám line
      AGV_BlindForward(&h_agv, 800);
      break;
    case ACT_BACKWARD:
      h_agv.direction = 1;
      // Đặc biệt: Tại các điểm 1, 4, 7 nếu quay 180 độ về 2, 5, 8 thì phải đi
      // thẳng dò line thêm 1.5s Chiều ngược lại (từ 2 về 1) sẽ KHÔNG chạy logic
      // này.
      if ((agv_state.current_node == 1 && next_node == 2) ||
          (agv_state.current_node == 4 && next_node == 5) ||
          (agv_state.current_node == 7 && next_node == 8)) {
        AGV_TrackLine_Sync(&h_agv, 1500);
      }
      AGV_Turn180_IMU(&h_agv, *current_heading);
      break;
    case ACT_STOP:
    default:
      AGV_Stop(&h_agv);
      break;
    }

    *current_heading = target_heading;
    agv_state.last_leave_intersection_time = HAL_GetTick();
    agv_state.follow_line_enable = true;
    *last_processed_node = 0xFFFF;

    // Đã qua ngã tư và cập nhật góc mới, lưu vào EEPROM
    // EEPROM_SaveState(agv_state.current_node, *current_heading);
  }
}

/* Hàm con hỗ trợ truyền SPI 16-bit tổng quát (hỗ trợ cấu hình động CPOL, CPHA) */
static uint16_t ScanLogic_SPI_Transfer_16(uint16_t tx_word, int cpol, int cpha, uint16_t pin_sdi, uint16_t pin_sdo) {
    uint16_t rx_word = 0;

    /* 1. Setup trạng thái Clock idle */
    HAL_GPIO_WritePin(GPIOB, GPIO_PIN_13, cpol ? GPIO_PIN_SET : GPIO_PIN_RESET);
    for (volatile int i = 0; i < 250; i++) __asm("nop");

    for (int8_t bit = 15; bit >= 0; bit--) {
        uint8_t mosi_bit = (tx_word >> bit) & 0x01;

        if (cpha == 0) {
            /* SPI Mode CPHA=0: MOSI được cập nhật trước cạnh đầu tiên */
            HAL_GPIO_WritePin(GPIOB, pin_sdi, mosi_bit ? GPIO_PIN_SET : GPIO_PIN_RESET);
            for (volatile int i = 0; i < 250; i++) __asm("nop");

            /* Cạnh đầu tiên (CLK đảo ngược trạng thái idle) -> Slave lấy mẫu, ta đọc SDO */
            HAL_GPIO_WritePin(GPIOB, GPIO_PIN_13, cpol ? GPIO_PIN_RESET : GPIO_PIN_SET);
            for (volatile int i = 0; i < 250; i++) __asm("nop");

            if (HAL_GPIO_ReadPin(GPIOB, pin_sdo) == GPIO_PIN_SET) {
                rx_word |= (1 << bit);
            }

            /* Cạnh thứ hai (CLK quay về trạng thái idle) */
            HAL_GPIO_WritePin(GPIOB, GPIO_PIN_13, cpol ? GPIO_PIN_SET : GPIO_PIN_RESET);
            for (volatile int i = 0; i < 250; i++) __asm("nop");
        } else {
            /* SPI Mode CPHA=1: Cạnh đầu tiên là cạnh dịch dữ liệu (Setup MOSI) */
            HAL_GPIO_WritePin(GPIOB, GPIO_PIN_13, cpol ? GPIO_PIN_RESET : GPIO_PIN_SET);
            HAL_GPIO_WritePin(GPIOB, pin_sdi, mosi_bit ? GPIO_PIN_SET : GPIO_PIN_RESET);
            for (volatile int i = 0; i < 250; i++) __asm("nop");

            /* Cạnh thứ hai là cạnh chốt dữ liệu (CLK quay về idle) -> Đọc SDO */
            HAL_GPIO_WritePin(GPIOB, GPIO_PIN_13, cpol ? GPIO_PIN_SET : GPIO_PIN_RESET);
            for (volatile int i = 0; i < 250; i++) __asm("nop");

            if (HAL_GPIO_ReadPin(GPIOB, pin_sdo) == GPIO_PIN_SET) {
                rx_word |= (1 << bit);
            }
        }
    }
    return rx_word;
}

void ADS8688_ScanLogic(void) {
    /* Quét tự động 16 combo (4 pinouts * 2 CPOL * 2 CPHA):
     * Pinout layout:
     * - layout = 0: Normal Pins (SDI=PB15, SDO=PB14, CS=PG12, RST=PG13)
     * - layout = 1: Swapped SDI/SDO (SDI=PB14, SDO=PB15, CS=PG12, RST=PG13)
     * - layout = 2: Swapped CS/RST (SDI=PB15, SDO=PB14, CS=PG13, RST=PG12)
     * - layout = 3: Swapped Both (SDI=PB14, SDO=PB15, CS=PG13, RST=PG12)
     *
     * combo = (pin_layout * 4) + (cpol * 2) + cpha
     */
    for (int combo = 0; combo < 16; combo++) {
        int pin_layout = combo / 4;
        int cpol       = (combo % 4) / 2;
        int cpha       = combo % 2;

        uint16_t pin_sdi = (pin_layout == 1 || pin_layout == 3) ? GPIO_PIN_14 : GPIO_PIN_15;
        uint16_t pin_sdo = (pin_layout == 1 || pin_layout == 3) ? GPIO_PIN_15 : GPIO_PIN_14;
        uint16_t pin_cs  = (pin_layout == 2 || pin_layout == 3) ? GPIO_PIN_13 : GPIO_PIN_12;
        uint16_t pin_rst = (pin_layout == 2 || pin_layout == 3) ? GPIO_PIN_12 : GPIO_PIN_13;

        /* Cấu hình chân GPIOB */
        GPIO_InitTypeDef gpio_b = {0};
        gpio_b.Pin = pin_sdi | GPIO_PIN_13; /* SDI và CLK (PB13) */
        gpio_b.Mode = GPIO_MODE_OUTPUT_PP;
        gpio_b.Pull = GPIO_NOPULL;
        gpio_b.Speed = GPIO_SPEED_FREQ_LOW;
        HAL_GPIO_Init(GPIOB, &gpio_b);

        gpio_b.Pin = pin_sdo;
        gpio_b.Mode = GPIO_MODE_INPUT;
        gpio_b.Pull = GPIO_NOPULL;
        HAL_GPIO_Init(GPIOB, &gpio_b);

        /* Cấu hình chân GPIOG */
        GPIO_InitTypeDef gpio_g = {0};
        gpio_g.Pin = pin_cs | pin_rst;
        gpio_g.Mode = GPIO_MODE_OUTPUT_PP;
        gpio_g.Pull = GPIO_NOPULL;
        gpio_g.Speed = GPIO_SPEED_FREQ_LOW;
        HAL_GPIO_Init(GPIOG, &gpio_g);

        /* 1. Reset chip (RST Active LOW) */
        HAL_GPIO_WritePin(GPIOG, pin_cs, GPIO_PIN_SET);  /* CS High */
        HAL_GPIO_WritePin(GPIOG, pin_rst, GPIO_PIN_RESET); /* RST Low (Reset) */
        HAL_Delay(5);
        HAL_GPIO_WritePin(GPIOG, pin_rst, GPIO_PIN_SET);   /* RST High (Run) */
        HAL_Delay(5);

        /* 2. Ghi dải đo CH0 = RANGE_0_5V (0x06)
         * Lệnh ghi: (0x05 << 1) | 0x01 = 0x0B (Byte cao), 0x06 (Byte thấp) */
        uint16_t tx_write = 0x0B06;
        HAL_GPIO_WritePin(GPIOG, pin_cs, GPIO_PIN_RESET); /* CS Low (Select) */
        ScanLogic_SPI_Transfer_16(tx_write, cpol, cpha, pin_sdi, pin_sdo);
        ScanLogic_SPI_Transfer_16(0x0000, cpol, cpha, pin_sdi, pin_sdo);
        HAL_GPIO_WritePin(GPIOG, pin_cs, GPIO_PIN_SET);   /* CS High (Idle) */
        HAL_Delay(5);

        /* 3. Đọc lại thanh ghi CH0_INPUT_RANGE (0x05)
         * Lệnh đọc: (0x05 << 1) & 0xFE = 0x0A (Byte cao), 0x00 (Byte thấp) */
        uint16_t tx_read = 0x0A00;

        /* Chu kỳ 1: Gửi lệnh đọc */
        HAL_GPIO_WritePin(GPIOG, pin_cs, GPIO_PIN_RESET);
        ScanLogic_SPI_Transfer_16(tx_read, cpol, cpha, pin_sdi, pin_sdo);
        ScanLogic_SPI_Transfer_16(0x0000, cpol, cpha, pin_sdi, pin_sdo);
        HAL_GPIO_WritePin(GPIOG, pin_cs, GPIO_PIN_SET);
        HAL_Delay(5);

        /* Chu kỳ 2: Gửi NO_OP (0x0000) và đọc dữ liệu */
        HAL_GPIO_WritePin(GPIOG, pin_cs, GPIO_PIN_RESET);
        uint16_t rx_high = ScanLogic_SPI_Transfer_16(0x0000, cpol, cpha, pin_sdi, pin_sdo);
        ScanLogic_SPI_Transfer_16(0x0000, cpol, cpha, pin_sdi, pin_sdo);
        HAL_GPIO_WritePin(GPIOG, pin_cs, GPIO_PIN_SET);

        dbg_ads_scan_results[combo] = (uint8_t)(rx_high & 0xFF);
        HAL_Delay(5);
    }

    /* Trả về cấu hình chân mặc định ban đầu */
    MX_GPIO_Init();
}

/* USER CODE END 0 */

int main(void) {

  /* MCU Configuration--------------------------------------------------------*/

  /* Reset of all peripherals, Initializes the Flash interface and the Systick.
   */
  HAL_Init();

  /* Configure the system clock */
  SystemClock_Config();

  /* Configure the peripherals common clocks */
  PeriphCommonClock_Config();

  /* Initialize all configured peripherals */
  MX_GPIO_Init();
  MX_GPDMA1_Init();
  MX_ICACHE_Init();
  MX_TIM3_Init();
  MX_TIM4_Init();
  MX_SPI1_Init();
  MX_UART5_Init();
  MX_USART1_UART_Init();
  MX_USART3_UART_Init();
  MX_TIM6_Init();
  MX_USART2_UART_Init();
  MX_SPI3_Init();
  /* USER CODE BEGIN 2 */
  step_Stop(); // Đảm bảo nhả phanh/không ghì động cơ bước lúc khởi động
  LineSensor_Init(&line_ss, sensor_ports, sensor_pins);

  // Khởi tạo Motor trái (PWM CH1) và phải (PWM CH2) trên TIM3 (Khớp phần cứng)
  htim3.Instance->PSC = 31;
  htim3.Instance->ARR = 999;

  Motor_Init(&m_left, &htim3, TIM_CHANNEL_1, B_Out23_GPIO_Port, B_Out23_Pin,
             B_Out22_GPIO_Port, B_Out22_Pin);
  Motor_Init(&m_right, &htim3, TIM_CHANNEL_2, B_Out21_GPIO_Port, B_Out21_Pin,
             B_Out20_GPIO_Port, B_Out20_Pin);

  m_right.InvertDirection = 1;

  pid_ctrl.Kp = 65.0f;
  pid_ctrl.Ki = 0.0f;
  pid_ctrl.Kd = 1.5f;
  pid_ctrl.i = 0.0f;

  AGV_Init(&h_agv, &m_left, &m_right, &line_ss, &pid_ctrl, 300.0f);
  LS7366R_InitAll();
  spi_test_result_e1 = LS7366R_TestSPI(1);
  spi_test_result_e2 = LS7366R_TestSPI(2);

  HMI_Init(&huart1, 1); // Đổi HMI sang USART1 (RS232)

  extern TIM_HandleTypeDef htim6;
  HAL_TIM_Base_Start_IT(&htim6);

  QR50_Init(&qr50, &huart2, 99); // Khởi tạo QR50 trên USART2 (RS485_1)
  Wiegand_Init(&h_wiegand);      // Khởi tạo Wiegand reader

  // Khởi động DMA cho QR50 (RS485_1)
  HAL_UARTEx_ReceiveToIdle_DMA(&huart2, qr50_rx_buffer, sizeof(qr50_rx_buffer));

  // DMA đã được HMI_Init khởi động cho HMI
  extern HMI_HandleTypeDef h_hmi;
  // Cố gắng start lại DMA cho HMI để chắc chắn (nếu HMI_Init có lỗi/trễ)
  HAL_UARTEx_ReceiveToIdle_DMA(&huart1, h_hmi.rx_buffer,
                               sizeof(h_hmi.rx_buffer));

  // Khởi tạo kênh giao tiếp Master-Slave với ESP32 qua UART5 (RS485_2)
  ESP32_Init(&huart5);

  Load_Factory_Map();
  //  EEPROM_EraseSector();
  // Đọc trạng thái cũ từ Flash EEPROM (nếu có)
  uint16_t saved_node;
  uint8_t saved_heading;
  if (EEPROM_LoadState(&saved_node, &saved_heading)) {
    agv_state.current_node = saved_node;
    current_heading = (AGV_Heading_t)saved_heading;
  }

  // Khởi động với đường đi trống - chờ HMI đặt đích mới tính
  path_length = 0;
  agv_state.path_index = 0;
  HAL_UART_Receive_IT(&huart3, (uint8_t *)&huart3_rx_byte, 1);
  HAL_Delay(2000);
  agv_state.last_qr_time = HAL_GetTick();
  uint32_t last_esp32_req_time = 0;
  uint32_t last_led_time = 0;

  /* Khởi tạo ADS8688 External ADC (bit-bang SPI) + Timer quét riêng */
  ADS8688_Init(&h_ads8688, ADS8688_RANGE_0_5V);

  /* Test SPI: đọc lại thanh ghi CH0 Input Range, kỳ vọng = 0x06 (RANGE_0_5V) */
  dbg_ads_spi_test = ADS8688_ReadReg(ADS8688_REG_CH0_INPUT_RANGE);

  /* Đọc trạng thái GPIO để chẩn đoán phần cứng */
  dbg_ads_pin_rst = HAL_GPIO_ReadPin(T_ADC_RST_GPIO_Port, T_ADC_RST_Pin);
  dbg_ads_pin_cs  = HAL_GPIO_ReadPin(T_ADC_CS_GPIO_Port, T_ADC_CS_Pin);
  dbg_ads_pin_sdo = HAL_GPIO_ReadPin(T_ADC_SDO_GPIO_Port, T_ADC_SDO_Pin);

  /* Quét tự động chẩn đoán pinout phần cứng */
  extern void ADS8688_ScanLogic(void);
  ADS8688_ScanLogic();

  MX_TIM7_Init();
  HAL_TIM_Base_Start_IT(&htim7);
  /* USER CODE END 2 */

  /* Infinite loop */
  while (1) {

    /* USER CODE BEGIN 3 */
    adc_feedback_ch0 = h_ads8688.voltage[0];

    AGV_UpdateGlobalYaw(); // Cập nhật góc Yaw toàn cục từ IMU
    HMI_Process();

    Wiegand_ProcessLoop(&h_wiegand);
    if (h_wiegand.new_data_ready) {
      debug_wiegand_id = h_wiegand.final_card_id;
      h_wiegand.new_data_ready = false;

      // Cập nhật last_qr_time tương tự như khi quét mã QR
      agv_state.last_qr_time = HAL_GetTick();

      // Ánh xạ Wiegand ID sang Node ID
      uint16_t read_node_id = 0xFFFF;
      for (int i = 0; i < MAX_NODES; i++) {
        if (rfid_node_map[i] == debug_wiegand_id && debug_wiegand_id != 0 &&
            debug_wiegand_id != 0xFFFFFFFF) {
          read_node_id = i;
          break;
        }
      }

      if (read_node_id != 0xFFFF && read_node_id != last_processed_node) {
        pending_qr_node = read_node_id;
      }
    }

    ESP32_SensorData_t safe_esp32_data = ESP32_GetSafeData();
    /* ARM FORWARD BLOCK - disabled while arms are physically disconnected
    static uint32_t last_arm_send_tick = 0;
    if (safe_esp32_data.HasNewArmCommandLeft ||
        safe_esp32_data.HasNewArmCommandRight ||
        safe_esp32_data.HasNewArmCommand) {
      ESP32_SensorData_t arm_snapshot;

      __disable_irq();
      arm_snapshot = esp32_data;
      esp32_data.HasNewArmCommand = false;
      esp32_data.HasNewArmCommandLeft = false;
      esp32_data.HasNewArmCommandRight = false;
      __enable_irq();

      // Right arm: Forward raw binary frame
      if (arm_snapshot.HasNewArmCommandRight) {
        if (arm_snapshot.RawArmCommandRight[0] == 0xAA &&
            arm_snapshot.RawArmCommandRight[1] == 0x55) {
          // Temporarily skipped to prevent unconnected UART3 hang
          // HAL_UART_Transmit(&huart3, (uint8_t *)arm_snapshot.RawArmCommandRight,
          //                   32, 50);
        }
      }
      // Left arm: Forward legacy text string
      if (arm_snapshot.HasNewArmCommandLeft) {
        AGV_ForwardArmCommand(arm_snapshot.ArmCommandLeft);
      }
      if (!arm_snapshot.HasNewArmCommandRight &&
          !arm_snapshot.HasNewArmCommandLeft && arm_snapshot.HasNewArmCommand) {
        if (AGV_IsLegacyArmCommand(arm_snapshot.ArmCommand)) {
          AGV_ForwardArmCommand(arm_snapshot.ArmCommand);
        }
      }

      last_arm_send_tick = HAL_GetTick();
    } else {
      if (HAL_GetTick() - last_arm_send_tick >= AGV_ARM_FORWARD_PERIOD_MS) {
        last_arm_send_tick = HAL_GetTick();

        // Right arm heartbeat (binary)
        if (safe_esp32_data.RawArmCommandRight[0] == 0xAA &&
            safe_esp32_data.RawArmCommandRight[1] == 0x55) {
          // Temporarily skipped to prevent unconnected UART3 hang
          // HAL_UART_Transmit(
          //     &huart3, (uint8_t *)safe_esp32_data.RawArmCommandRight, 32, 50);
        }

        // Left arm heartbeat (text)
        if (AGV_IsLegacyArmCommand(safe_esp32_data.ArmCommandLeft)) {
          AGV_ForwardArmCommand(safe_esp32_data.ArmCommandLeft);
        }

        // Fallback
        if (!AGV_IsLegacyArmCommand(safe_esp32_data.ArmCommandLeft) &&
            safe_esp32_data.RawArmCommandRight[0] != 0xAA &&
            AGV_IsLegacyArmCommand(safe_esp32_data.ArmCommand)) {
          AGV_ForwardArmCommand(safe_esp32_data.ArmCommand);
        }
      }
    }
    ARM FORWARD BLOCK END */

    // 1. Service communication first so we never lose sensor updates or deadlock
    AGV_ServiceEsp32Request(&last_esp32_req_time);
    AGV_ServiceHeartbeat(&last_led_time);

    // 2. Safety handling and navigation bypass
    AGV_HandleEsp32Safety(&h_agv, &safe_esp32_data);
    if (safe_esp32_data.IsConnected &&
        (safe_esp32_data.Yaw == 65535.0f ||
         safe_esp32_data.ObstacleDistance == 0xFFFF)) {
      continue;
    }

    if (safe_esp32_data.HasNewCommand) {
      esp32_data.HasNewCommand = false;
      esp32_data.TargetNode = safe_esp32_data.TargetNode;
      esp32_data.H_Command = safe_esp32_data.H_Command;
      if (safe_esp32_data.TargetNode != agv_state.destination_node) {
        agv_state.destination_node = safe_esp32_data.TargetNode;
        agv_state.need_recalculate_path = true;

        // Đồng bộ ngược lại cho màn hình HMI biết ESP32 đã đổi đích đến
        extern uint16_t hmi_registers[];
        hmi_registers[0x05] =
            agv_state.destination_node; // 0x05 is REG_DEST_NODE
      }

      if (safe_esp32_data.H_Command != 0 && safe_esp32_data.H_Command != 255) {
        extern uint16_t hmi_registers[];
        hmi_registers[0x06] = safe_esp32_data.H_Command; // 0x06 is REG_COMMAND
      }
    }

    HMI_SyncData();

    if (agv_state.need_recalculate_path) {
      agv_state.need_recalculate_path = false;

      if (agv_state.follow_line_enable && path_length > 0 &&
          agv_state.path_index < path_length - 1) {
        uint16_t next_node = current_path[agv_state.path_index + 1];
        uint16_t new_path[MAX_NODES];
        uint16_t new_len = 0;

        bool found =
            Routing_Dijkstra(&factory_map, next_node,
                             agv_state.destination_node, new_path, &new_len);
        if (found) {
          for (uint16_t i = 0; i < new_len; i++) {
            if (agv_state.path_index + 1 + i < MAX_NODES) {
              current_path[agv_state.path_index + 1 + i] = new_path[i];
            }
          }
          path_length = agv_state.path_index + 1 + new_len;
        }
      } else {
        bool found = Routing_Dijkstra(&factory_map, agv_state.current_node,
                                      agv_state.destination_node, current_path,
                                      &path_length);
        if (found) {
          agv_state.path_index = 0;
          if (path_length > 1) {
            uint16_t next_node = current_path[1];
            AGV_Heading_t target_heading = Routing_GetHeading(
                &factory_map, agv_state.current_node, next_node);

            // Nếu xe đang bị mất phương hướng do bắt cóc, ép hướng về hướng
            // đích
            if (agv_state.is_kidnapped) {
              current_heading = target_heading;
              agv_state.is_kidnapped = false;
            }

            int diff = (target_heading - current_heading + 4) % 4;
            uint32_t fwd_delay = 1900;
            float search_ratio = 0.70f;
            if (agv_state.current_node == 8 && next_node == 7) {
              fwd_delay = 1600;
            }

            AGV_Action_t next_action = (AGV_Action_t)diff;
            switch (next_action) {
            case ACT_TURN_LEFT:
              h_agv.direction = 1;
              AGV_TurnLeft_IMU(&h_agv, fwd_delay, search_ratio);
              break;
            case ACT_TURN_RIGHT:
              h_agv.direction = 1;
              AGV_TurnRight_IMU(&h_agv, fwd_delay, search_ratio);
              break;
            case ACT_BACKWARD:
              h_agv.direction = 1;
              AGV_Turn180_IMU(&h_agv, current_heading);
              break;
            case ACT_STRAIGHT:
            case ACT_STOP:
            default:
              break;
            }
            current_heading = target_heading;

            // Kiểm tra xem sau khi rẽ, góc của xe có khớp với bản đồ không
            if (!AGV_ValidateHeading((uint8_t)current_heading)) {
              AGV_Stop(&h_agv);
              agv_state.follow_line_enable = false;
              agv_state.indicator_state = 2; // Báo lỗi
              continue; // Bỏ qua đoạn lệnh tiếp theo, yêu cầu can thiệp
            }
          }

          agv_state.follow_line_enable = true;
          agv_state.indicator_state = 0;
          agv_state.last_leave_intersection_time = HAL_GetTick();
          agv_state.last_qr_time = HAL_GetTick();
        } else {
          path_length = 0;
        }
      }
    }

    if (agv_state.run_mode == MODE_8_TEST_ENCODER) {
      static uint32_t m8_start = 0;
      if (m8_start == 0)
        m8_start = HAL_GetTick();

      if (HAL_GetTick() - m8_start > 1000) {
        Motor_SetSpeed(&m_left, 100);
        Motor_SetSpeed(&m_right, 100);
      } else {
        AGV_Stop(&h_agv);
      }
      continue;
    }
    if (agv_state.run_mode == MODE_5_CALIBRATE_MOTORS) {
      if (AGV_HandleMode5Calibration()) {
        continue;
      }
    }

    if (qr50.Data.New_Data_Flag) {
      qr50.Data.New_Data_Flag = false;

      // QR50 gửi xuống theo format N00 -> N08.
      // Parse chặt để tránh nhận nhầm các chuỗi rác/không đủ định dạng.
      if (qr50.Data.Data_Length >= 3 && qr50.Data.Data_Buffer[0] == 'N' &&
          qr50.Data.Data_Buffer[1] >= '0' && qr50.Data.Data_Buffer[1] <= '9' &&
          qr50.Data.Data_Buffer[2] >= '0' && qr50.Data.Data_Buffer[2] <= '9') {
        uint16_t read_node_id =
            (uint16_t)((qr50.Data.Data_Buffer[1] - '0') * 10 +
                       (qr50.Data.Data_Buffer[2] - '0'));

        if (read_node_id < MAX_NODES && read_node_id != last_processed_node) {
          agv_state.last_qr_time = HAL_GetTick();
          pending_qr_node = read_node_id;
        }
      }
    }

    if (agv_state.is_at_intersection) {
      AGV_HandleIntersectionRouting(&pending_qr_node, &last_processed_node,
                                    &path_length, &current_heading);
    }

    // chay Step
    cmd.angle = dbg_huart3_joints_left[0];
    if (cmd.angle != cmd_prev.angle || cmd.rpm != cmd_prev.rpm) {
      cmd_prev = cmd;
      step_Run(&cmd);
    }
  }
  /* USER CODE END 3 */
}

void SystemClock_Config(void) {
  RCC_OscInitTypeDef RCC_OscInitStruct = {0};
  RCC_ClkInitTypeDef RCC_ClkInitStruct = {0};

  /** Configure the main internal regulator output voltage
   */
  __HAL_PWR_VOLTAGESCALING_CONFIG(PWR_REGULATOR_VOLTAGE_SCALE0);

  while (!__HAL_PWR_GET_FLAG(PWR_FLAG_VOSRDY)) {
  }

  /** Initializes the RCC Oscillators according to the specified parameters
   * in the RCC_OscInitTypeDef structure.
   */
  RCC_OscInitStruct.OscillatorType =
      RCC_OSCILLATORTYPE_LSI | RCC_OSCILLATORTYPE_HSE;
  RCC_OscInitStruct.HSEState = RCC_HSE_ON;
  RCC_OscInitStruct.LSIState = RCC_LSI_ON;
  RCC_OscInitStruct.PLL.PLLState = RCC_PLL_ON;
  RCC_OscInitStruct.PLL.PLLSource = RCC_PLL1_SOURCE_HSE;
  RCC_OscInitStruct.PLL.PLLM = 1;
  RCC_OscInitStruct.PLL.PLLN = 62;
  RCC_OscInitStruct.PLL.PLLP = 2;
  RCC_OscInitStruct.PLL.PLLQ = 4;
  RCC_OscInitStruct.PLL.PLLR = 2;
  RCC_OscInitStruct.PLL.PLLRGE = RCC_PLL1_VCIRANGE_3;
  RCC_OscInitStruct.PLL.PLLVCOSEL = RCC_PLL1_VCORANGE_WIDE;
  RCC_OscInitStruct.PLL.PLLFRACN = 4096;
  if (HAL_RCC_OscConfig(&RCC_OscInitStruct) != HAL_OK) {
    Error_Handler();
  }

  /** Initializes the CPU, AHB and APB buses clocks
   */
  RCC_ClkInitStruct.ClockType = RCC_CLOCKTYPE_HCLK | RCC_CLOCKTYPE_SYSCLK |
                                RCC_CLOCKTYPE_PCLK1 | RCC_CLOCKTYPE_PCLK2 |
                                RCC_CLOCKTYPE_PCLK3;
  RCC_ClkInitStruct.SYSCLKSource = RCC_SYSCLKSOURCE_PLLCLK;
  RCC_ClkInitStruct.AHBCLKDivider = RCC_SYSCLK_DIV1;
  RCC_ClkInitStruct.APB1CLKDivider = RCC_HCLK_DIV1;
  RCC_ClkInitStruct.APB2CLKDivider = RCC_HCLK_DIV1;
  RCC_ClkInitStruct.APB3CLKDivider = RCC_HCLK_DIV1;

  if (HAL_RCC_ClockConfig(&RCC_ClkInitStruct, FLASH_LATENCY_5) != HAL_OK) {
    Error_Handler();
  }

  /** Enables the Clock Security System
   */
  HAL_RCC_EnableCSS();

  /** Configure the programming delay
   */
  __HAL_FLASH_SET_PROGRAM_DELAY(FLASH_PROGRAMMING_DELAY_2);
}

void PeriphCommonClock_Config(void) {
  RCC_PeriphCLKInitTypeDef PeriphClkInitStruct = {0};

  /** Initializes the peripherals clock
   */
  PeriphClkInitStruct.PeriphClockSelection = RCC_PERIPHCLK_CKPER;
  PeriphClkInitStruct.CkperClockSelection = RCC_CLKPSOURCE_HSI;
  if (HAL_RCCEx_PeriphCLKConfig(&PeriphClkInitStruct) != HAL_OK) {
    Error_Handler();
  }
}

/* USER CODE BEGIN 4 */
// Cờ toàn cục: khi STM32 đang truyền TX, cấm ErrorCallback restart DMA
volatile bool hmi_tx_in_progress = false;
volatile uint32_t debug_hmi_crc_err = 0;
volatile uint32_t debug_hmi_hw_err = 0;

void HAL_UART_ErrorCallback(UART_HandleTypeDef *huart) {
  if (huart->Instance == USART1) {
    debug_hmi_hw_err++; // Tăng biến này nếu HMI nhận rác do nhiễu motor

    // Xóa cờ lỗi UART
    __HAL_UART_CLEAR_FLAG(huart, UART_CLEAR_OREF | UART_CLEAR_NEF |
                                     UART_CLEAR_FEF | UART_CLEAR_PEF);

    // Nếu đang trong quá trình truyền TX, KHÔNG restart DMA (để HMI_Process tự
    // xử lý)
    if (hmi_tx_in_progress)
      return;

    // Chỉ restart DMA khi đang ở chế độ nhận bình thường
    HAL_UART_AbortReceive(huart);
    extern HMI_HandleTypeDef h_hmi;
    HAL_UARTEx_ReceiveToIdle_DMA(h_hmi.huart, h_hmi.rx_buffer,
                                 sizeof(h_hmi.rx_buffer));
  } else if (huart->Instance == USART2) {
    debug_qr_err_count++; // Tăng biến đếm lỗi
    // Xóa cờ lỗi UART
    __HAL_UART_CLEAR_FLAG(huart, UART_CLEAR_OREF | UART_CLEAR_NEF |
                                     UART_CLEAR_FEF | UART_CLEAR_PEF);

    HAL_UART_AbortReceive(huart);
    extern uint8_t qr50_rx_buffer[QR50_MAX_DATA_LEN];
    HAL_UARTEx_ReceiveToIdle_DMA(huart, qr50_rx_buffer, sizeof(qr50_rx_buffer));
  } else if (huart->Instance == UART5) {
    // Xóa cờ lỗi UART
    __HAL_UART_CLEAR_FLAG(huart, UART_CLEAR_OREF | UART_CLEAR_NEF |
                                     UART_CLEAR_FEF | UART_CLEAR_PEF);

    HAL_UART_AbortReceive(huart);
    extern uint8_t esp32_rx_buffer[128];
    HAL_UARTEx_ReceiveToIdle_DMA(huart, esp32_rx_buffer,
                                 sizeof(esp32_rx_buffer));
  } else if (huart->Instance == USART3) {
    __HAL_UART_CLEAR_FLAG(huart, UART_CLEAR_OREF | UART_CLEAR_NEF |
                                     UART_CLEAR_FEF | UART_CLEAR_PEF);
    HAL_UART_AbortReceive(huart);
    HAL_UART_Receive_IT(huart, (uint8_t *)&huart3_rx_byte, 1);
  }
}

void HAL_UART_RxCpltCallback(UART_HandleTypeDef *huart) {
  if (huart->Instance == USART3) {
    dbg_huart3_rx_byte_count++;
    char c = (char)huart3_rx_byte;

    if (c == '\n' || c == '\r') {
      if (huart3_rx_line_idx > 0) {
        huart3_rx_line[huart3_rx_line_idx] = '\0';

        char *star = strchr(huart3_rx_line, '*');
        if (star != NULL) {
          *star = '\0';
          char *checksum_str = star + 1;

          uint8_t calc_sum = 0;
          for (char *c_ptr = huart3_rx_line; c_ptr < star; c_ptr++) {
            calc_sum ^= (uint8_t)(*c_ptr);
          }

          uint8_t rx_sum = 0;
          char h1 = checksum_str[0];
          char h2 = checksum_str[1];
          int valid_hex = 1;
          if (h1 >= '0' && h1 <= '9') rx_sum += (h1 - '0') << 4;
          else if (h1 >= 'A' && h1 <= 'F') rx_sum += (h1 - 'A' + 10) << 4;
          else if (h1 >= 'a' && h1 <= 'f') rx_sum += (h1 - 'a' + 10) << 4;
          else valid_hex = 0;

          if (h2 >= '0' && h2 <= '9') rx_sum += (h2 - '0');
          else if (h2 >= 'A' && h2 <= 'F') rx_sum += (h2 - 'A' + 10);
          else if (h2 >= 'a' && h2 <= 'f') rx_sum += (h2 - 'a' + 10);
          else valid_hex = 0;

          if (valid_hex && (calc_sum == rx_sum)) {
            if ((huart3_rx_line[0] == 'L' || huart3_rx_line[0] == 'R') && huart3_rx_line[1] == ':') {
              char *p = huart3_rx_line + 2;
              long q[6];
              int i = 0;
              for (i = 0; i < 6; i++) {
                while (*p == ',' || *p == ' ') p++;
                if (*p == '\0') break;
                char *next_p;
                q[i] = strtol(p, &next_p, 10);
                if (p == next_p) break;
                p = next_p;
              }

              if (i == 6) {
                dbg_huart3_rx_ok++;
                dbg_huart3_last_type = huart3_rx_line[0];
                if (dbg_huart3_last_type == 'L') {
                  dbg_huart3_joints_left[0] = ((float)q[0] / 100.0f) / 15.0f*50.0f;
                  for (int j = 1; j < 6; j++) {
                    dbg_huart3_joints_left[j] = (float)q[j] / 100.0f;
                  }
                } else if (dbg_huart3_last_type == 'R') {
                  dbg_huart3_joints_right[0] = ((float)q[0] / 100.0f) / 15.0f*50.0f;
                  for (int j = 1; j < 6; j++) {
                    dbg_huart3_joints_right[j] = (float)q[j] / 100.0f;
                  }
                }
              } else {
                dbg_huart3_rx_err++;
              }
            } else {
              dbg_huart3_rx_err++;
            }
          } else {
            dbg_huart3_rx_err++;
          }
        } else {
          dbg_huart3_rx_err++;
        }

        huart3_rx_line_idx = 0;
      }
    } else {
      if (huart3_rx_line_idx < sizeof(huart3_rx_line) - 1) {
        huart3_rx_line[huart3_rx_line_idx++] = c;
      } else {
        huart3_rx_line_idx = 0;
        dbg_huart3_rx_err++;
      }
    }

    HAL_UART_Receive_IT(&huart3, (uint8_t *)&huart3_rx_byte, 1);
  }
}

void HAL_UARTEx_RxEventCallback(UART_HandleTypeDef *huart, uint16_t Size) {
  if (huart->Instance == USART1) { // RS232 (Dành riêng cho HMI)
    extern HMI_HandleTypeDef h_hmi;
    debug_hmi_rx_count++; // Debug đếm số lần nhận từ HMI

    if (Size >= 8 && h_hmi.rx_buffer[0] == h_hmi.slave_address) {
      HMI_RxCallback(huart, Size);
    } else {
      // Phục hồi lại cơ chế abort UART và restart DMA cho HMI nếu bị lỗi
      HAL_UART_AbortReceive(huart);
      __HAL_UART_CLEAR_FLAG(huart,
                            UART_CLEAR_OREF | UART_CLEAR_NEF | UART_CLEAR_FEF);
      HAL_UARTEx_ReceiveToIdle_DMA(huart, h_hmi.rx_buffer,
                                   sizeof(h_hmi.rx_buffer));
    }
  } else if (huart->Instance == USART2) { // RS485_1 (Dành riêng cho QR50)
    extern uint8_t qr50_rx_buffer[QR50_MAX_DATA_LEN];
    debug_qr_rx_count++; // Debug đếm số lần nhận
    if (Size > 0) {
      QR50_ParseData(&qr50, qr50_rx_buffer, Size);
    }

    // Khởi động lại DMA sau khi nhận
    HAL_UART_AbortReceive(huart);
    __HAL_UART_CLEAR_FLAG(huart,
                          UART_CLEAR_OREF | UART_CLEAR_NEF | UART_CLEAR_FEF);
    HAL_UARTEx_ReceiveToIdle_DMA(huart, qr50_rx_buffer, sizeof(qr50_rx_buffer));
  } else if (huart->Instance == UART5) { // RS485_2 (ESP32 Sensor Hub)
    ESP32_ParseResponse(Size);

    // Khởi động lại DMA cho ESP32 sau khi nhận xong
    // (HAL_UARTEx_ReceiveToIdle_DMA tự động dừng sau 1 frame)
    HAL_UART_AbortReceive(huart);
    __HAL_UART_CLEAR_FLAG(huart,
                          UART_CLEAR_OREF | UART_CLEAR_NEF | UART_CLEAR_FEF);
    extern uint8_t esp32_rx_buffer[128];
    HAL_UARTEx_ReceiveToIdle_DMA(huart, esp32_rx_buffer,
                                 sizeof(esp32_rx_buffer));
  }
}

void HAL_TIM_PeriodElapsedCallback(TIM_HandleTypeDef *htim) {
  if (htim->Instance == TIM3) {
    step_TIM_Callback(htim);
  }
  if (htim->Instance == TIM6) {
    // Luôn luôn đọc cảm biến line để phục vụ việc xem trên Live Watch (giống
    // code cũ của bạn)
    uint16_t val = LineSensor_Read(&line_ss);
    for (int i = 0; i < 16; i++) {
      debug_line_binary[i] = (val & (1 << (15 - i))) ? '1' : '0';
    }
    debug_line_binary[16] = '\0';

    // Luôn cập nhật trạng thái Encoder mỗi 10ms (dt = 0.01s)
    encoder_data.count_e1 = LS7366R_ReadCounter(ENC_CS1);
    encoder_data.count_e2 = LS7366R_ReadCounter(ENC_CS2);
    encoder_data.count_e3 = LS7366R_ReadCounter(ENC_CS3);
    encoder_data.count_e4 = LS7366R_ReadCounter(ENC_CS4);

    encoder_data.vel_e1 = LS7366R_GetVelocity(ENC_CS1, 0.01f);
    encoder_data.vel_e2 = LS7366R_GetVelocity(ENC_CS2, 0.01f);
    encoder_data.vel_e3 = LS7366R_GetVelocity(ENC_CS3, 0.01f);
    encoder_data.vel_e4 = LS7366R_GetVelocity(ENC_CS4, 0.01f);

    encoder_data.last_update = HAL_GetTick();

    // Ngắt PID mỗi 10ms - Chỉ điều khiển Motor nếu cờ được bật
    if (agv_state.follow_line_enable) {
      AGV_FollowLine(&h_agv);
    }
  }
  if (htim->Instance == TIM7) {
    dbg_tim7_count++;
    ADS8688_ReadAll(&h_ads8688);
    dbg_ads_raw0 = h_ads8688.raw[0];
    dbg_ads_raw1 = h_ads8688.raw[1];
  }
}

void HAL_GPIO_EXTI_Falling_Callback(uint16_t GPIO_Pin) {
  if (GPIO_Pin == WG0_Pin) {
    Wiegand_ProcessBit(&h_wiegand, 0);
  } else if (GPIO_Pin == WG1_Pin) {
    Wiegand_ProcessBit(&h_wiegand, 1);
  }
}
/* USER CODE END 4 */

void Error_Handler(void) {
  __disable_irq();
  while (1) {
  }
}
#ifdef USE_FULL_ASSERT
/**
 * @brief  Reports the name of the source file and the source line number
 *         where the assert_param error has occurred.
 * @param  file: pointer to the source file name
 * @param  line: assert_param error line source number
 * @retval None
 */
void assert_failed(uint8_t *file, uint32_t line) {
  /* USER CODE BEGIN 6 */
  /* User can add his own implementation to report the file name and line
     number, ex: printf("Wrong parameters value: file %s on line %d\r\n", file,
     line) */
  /* USER CODE END 6 */
}
#endif /* USE_FULL_ASSERT */
